# YTM32B1ME0 register map
Vendor: YTMicro; File version: 1.6
CPU: CM33 r0p4, little endian, MPU, FPU, 2 interrupt priority bits
Registers are 32-bit, read-write, reset 0x0 unless marked. A register's access mark holds for its fields unless they carry their own. Offsets are from the block's base; [hi:lo] are bit positions; {n}, {i} and the like mark numbered series.

## PTU0 — Programmable Trigger Unit
Base 0x40046000; register names take the prefix PTU0_
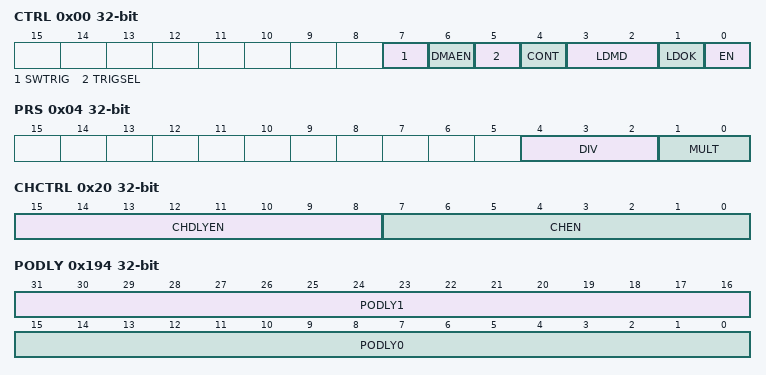
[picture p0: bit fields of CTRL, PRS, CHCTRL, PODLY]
0x00 CTRL — Control Register
  [7] SWTRIG wo — Trigger PTU by software.
    0=No effects; 1=If PTU is enabled and the trigger input source is software trigger, write 1 to this bit to generate a trigger input event
  [6] DMAEN — This bit is set and cleared by software to enable the generation of DMA requests. This allows using the DMA controller to manage automatically the converted data.
    0=DMA disabled; 1=DMA enabled
  [5] TRIGSEL — This bit selects the trigger input source for the PTU.
    0=External trigger is selected as the trigger input source; 1=Software trigger is selected as the trigger input source
  [4] CONT — Enables continuous mode.
    0=PTU operation in normal mode; 1=PTU operation in continuous mode
  [3:2] LDMD — Selects the mode to load the MOD, INTDLY, CHDLYn and PODLY registers, after 1 is written to LDOK.
    0=The internal registers are loaded with the values from their buffers immediately after 1 is written to LDOK; 1=The internal registers are loaded with the values from their buffers when the PTU counter reaches the MOD register value after 1 is written to LDOK; 2=The internal registers are loaded with the values from their buffers when a trigger input event is detected after 1 is written to LDOK; 3=The internal registers are loaded with the values from their buffers when either the PTU counter reaches the MOD register value or a trigger input event is detected after 1 is written to LDOK
  [1] LDOK — LDOK can be written only when CTRL[EN] is set or it can be written at the same time with CTRL[EN] being written to 1. it is automatically cleared when the values in buffers are loaded into the internal registers or the CTRL[EN] is cleared.
    0=Writing 0 to it has no effect; 1=Loading internal registers as selected load mode as value of CTRL[LDMD]
  [0] EN — Writing 1 to this bit updates the internal registers of MOD, INTDLY and CHDLYn with the values written to their buffers. The MOD, INTDLY and CHDLYn will take effect immediately if LDMD is cleared; or when the counter rolls over in Continuous mode, or a rising edge is detected on the selected trigger input source, or software trigger is selected and CTRL[SWTRIG] is written with 1, if CTRL[LDMD] is set. After 1 is written to LDOK bit, the values in the buffers of the above registers are not effective and the buffers cannot be written until the values in buffers are loaded into their internal registers.
    0=PTU disabled. The Counter is off.; 1=PTU enabled
0x04 PRS — Prescaler select register
  [4:2] DIV
    0=Counting uses the peripheral clock divided by multiplication factor selected by PRS[MULT]; 1=Counting uses the peripheral clock divided by twice of the multiplication factor selected by PRS[MULT]; 2=Counting uses the peripheral clock divided by 4 times of the multiplication factor selected by PRS[MULT]; 3=Counting uses the peripheral clock divided by 8 times of the multiplication factor selected by PRS[MULT]; 4=Counting uses the peripheral clock divided by 16 times of the multiplication factor selected by PRS[MULT]; 5=Counting uses the peripheral clock divided by 32 times of the multiplication factor selected by PRS[MULT]; 6=Counting uses the peripheral clock divided by 64 times of the multiplication factor selected by PRS[MULT]; 7=Counting uses the peripheral clock divided by 128 times of the multiplication factor selected by PRS[MULT]
  [1:0] MULT — This bit selects the multiplication factor of the prescaler divider for the counter clock.
    0=Multiplication factor is 1; 1=Multiplication factor is 10; 2=Multiplication factor is 20; 3=Multiplication factor is 40
0x08 INTE — Interrupt enable register
  [0] IE — This bit enables the PTU interrupt. When this bit is set, STS[IF] generates a PTU interrupt to the CPU.
    0=PTU interrupt disabled; 1=PTU interrupt enabled
0x0C STS — Interrupt flag register
  [0] IF — This bit is set when the counter value is equal to the internal buffer of the INTDLY register. Writing 1 clear this bit.
    0=This bit is 0 before the counter value is equal to the internal buffer of the INTDLY register; 1=This bit is set when the counter value is equal to the internal buffer of the INTDLY register
0x10 MOD reset 0xFFFF — Modulus Register
  [15:0] MOD — This modulus register controls the counter operation, when the counter reaches modulus value, it returns to zero. It always operate in Continuous mode. Reading this register returns the effective value of counter modulus.
0x14 CNT — Counter current value
  [15:0] CNT ro — Reading this register returns the current value of PTU counter.
0x18 INTDLY reset 0xFFFF — Interrupt delay register
  [15:0] INTDLY — This register specify the delay of generating PTU interrupt. A PTU interrupt is generated when the counter reaches the value of INTDLY[INTDLY].
0x20 CHCTRL — Channel control register
  [15:8] CHDLYEN
    0=Channel trigger number n scale delay disable; 1=Chanel trigger number n scale delay enable
  [7:0] CHEN — Channel trigger number n enable
    0=trigger number n disabled; 1=trigger number n enabled
0x24 CHSTS — Channel Status Register
  [23:16] CHF — The CHF[n] bit is set when the PTU counter matches the CHDLYn. Write 1 to clear these bits.
    0=Before the PTU counter matches the CHDLYn, CHF[n] bit is 0; 1=When the PTU counter matches the CHDLYn, CHF[n] bit is set
{0x28+4i} CHDLYn{i} (i=0..7) — PTU Channel Delay n Register
  [15:0] CHDLYn — This register specify the delay value for each of channels to generate the triggers which will start a ADC conversion when PTU counter reaches CHDLYn[CHDLYn] value. Reading this register returns the effective value.
0x190 POEN — PTU pulse-out enable register
  [0] POEN — This bit enable the pulse output.
    0=PTU pulse-out disabled; 1=PTU pulse-out enabled
0x194 PODLY — PTU pulse-out delay
  [31:16] PODLY1 — These bits specify the delay 1 value for the PTU pulse-out. Pulse-out goes low when the PTU counter is equal to the PODLY1. Reading these bits returns the value of internal register that is effective for the current PTU cycle.
  [15:0] PODLY0 — These bits specify the delay 0 value for the PTU Pulse-Out. Pulse-out goes high when the PTU counter is equal to the PODLY0. Reading these bits returns the value of internal register that is effective for the current PTU cycle.

## PTU1 — Programmable Trigger Unit
Base 0x40047000; register names take the prefix PTU1_
Registers as PTU0.
